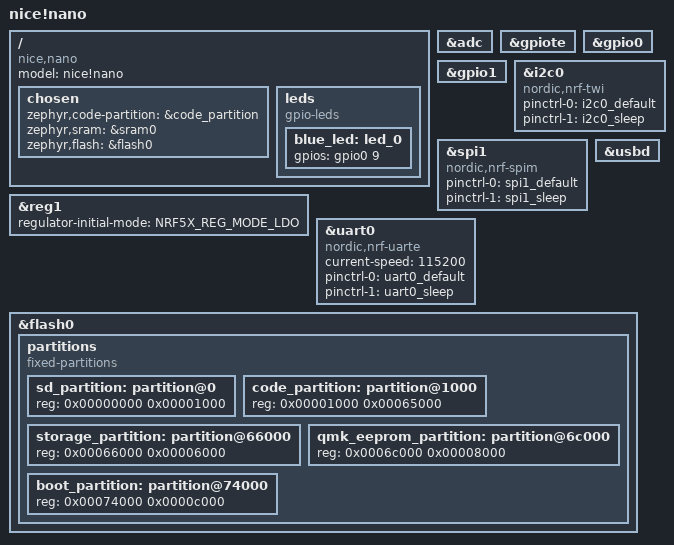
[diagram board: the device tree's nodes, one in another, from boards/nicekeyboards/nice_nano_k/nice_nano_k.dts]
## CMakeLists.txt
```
cmake_minimum_required(VERSION 3.13.1)

set(CONFIG_APPLICATION_DEFINED_SYSCALL true)
#D:/project/GitHub/zmkesb/zmk/zmk-feature-split-esb
set(ZEPHYR_BOARD_ALIASES "boards/aliases.cmake")
set(ZEPHYR_EXTRA_MODULES "${ZMK_EXTRA_MODULES};${CMAKE_CURRENT_SOURCE_DIR}/module;${CMAKE_CURRENT_SOURCE_DIR}/keymap-module")
message(STATUS "111111: ${CMAKE_CURRENT_SOURCE_DIR}")
list(APPEND ZEPHYR_EXTRA_MODULES
  "D:/project/GitHub/zmkesb/zmk-feature-split-esb-damex"
  # ${CMAKE_CURRENT_SOURCE_DIR}/../nrf
  # ${CMAKE_CURRENT_SOURCE_DIR}/../nrfxlib
)


# Find Zephyr. This also loads Zephyr's build system.
find_package(Zephyr REQUIRED HINTS ../zephyr)
project(zmk)

zephyr_linker_sources(SECTIONS include/linker/zmk-behaviors.ld)
zephyr_linker_sources(RODATA include/linker/zmk-events.ld)

if(CONFIG_ZMK_BEHAVIOR_LOCAL_IDS)
  zephyr_linker_sources(DATA_SECTIONS include/linker/zmk-behavior-local-id-map.ld)
endif()

zephyr_syscall_header(${APPLICATION_SOURCE_DIR}/include/drivers/behavior.h)
zephyr_syscall_header(${APPLICATION_SOURCE_DIR}/include/drivers/input_processor.h)
zephyr_syscall_header(${APPLICATION_SOURCE_DIR}/include/drivers/ext_power.h)

# Add your source file to the "app" target. This must come after
# find_package(Zephyr) which defines the target.
target_include_directories(app PRIVATE include)
add_subdirectory(src/boot)
target_sources(app PRIVATE src/stdlib.c)
target_sources(app PRIVATE src/activity.c)
target_sources(app PRIVATE src/behavior.c)
target_sources_ifdef(CONFIG_ZMK_KSCAN_SIDEBAND_BEHAVIORS app PRIVATE src/kscan_sideband_behaviors.c)
target_sources(app PRIVATE src/matrix_transform.c)
target_sources(app PRIVATE src/physical_layouts.c)
target_sources(app PRIVATE src/sensors.c)
target_sources_ifdef(CONFIG_ZMK_WPM app PRIVATE src/wpm.c)
target_sources(app PRIVATE src/event_manager.c)
target_sources_ifdef(CONFIG_ZMK_PM app PRIVATE src/pm.c)
target_sources_ifdef(CONFIG_ZMK_EXT_POWER app PRIVATE src/ext_power_generic.c)
target_sources_ifdef(CONFIG_ZMK_GPIO_KEY_WAKEUP_TRIGGER app PRIVATE src/gpio_key_wakeup_trigger.c)
target_sources(app PRIVATE src/events/activity_state_changed.c)
target_sources(app PRIVATE src/events/position_state_changed.c)
target_sources(app PRIVATE src/events/sensor_event.c)
target_sources_ifdef(CONFIG_ZMK_WPM app PRIVATE src/events/wpm_state_changed.c)
target_sources_ifdef(CONFIG_USB_DEVICE_STACK app PRIVATE src/events/usb_conn_state_changed.c)
target_sources(app PRIVATE src/behaviors/behavior_reset.c)
target_sources_ifdef(CONFIG_ZMK_EXT_POWER app PRIVATE src/behaviors/behavior_ext_power.c)
target_sources_ifdef(CONFIG_ZMK_BEHAVIOR_SOFT_OFF app PRIVATE src/behaviors/behavior_soft_off.c)
add_subdirectory_ifdef(CONFIG_ZMK_POINTING src/pointing/)
if ((NOT CONFIG_ZMK_SPLIT) OR CONFIG_ZMK_SPLIT_ROLE_CENTRAL)
  target_sources(app PRIVATE src/hid.c)
  target_sources(app PRIVATE src/behaviors/behavior_key_press.c)
  target_sources_ifdef(CONFIG_ZMK_BEHAVIOR_KEY_TOGGLE app PRIVATE src/behaviors/behavior_key_toggle.c)
  target_sources_ifdef(CONFIG_ZMK_BEHAVIOR_HOLD_TAP app PRIVATE src/behaviors/behavior_hold_tap.c)
  target_sources_ifdef(CONFIG_ZMK_BEHAVIOR_STICKY_KEY app PRIVATE src/behaviors/behavior_sticky_key.c)
  target_sources(app PRIVATE src/behaviors/behavior_caps_word.c)
  target_sources(app PRIVATE src/behaviors/behavior_key_repeat.c)
  target_sources_ifdef(CONFIG_ZMK_BEHAVIOR_MACRO app PRIVATE src/behaviors/behavior_macro.c)
  target_sources(app PRIVATE src/behaviors/behavior_momentary_layer.c)
  target_sources(app PRIVATE src/behaviors/behavior_mod_morph.c)
  target_sources(app PRIVATE src/behaviors/behavior_outputs.c)
  target_sources(app PRIVATE src/behaviors/behavior_toggle_layer.c)
  target_sources(app PRIVATE src/behaviors/behavior_to_layer.c)
  target_sources(app PRIVATE src/behaviors/behavior_transparent.c)
  target_sources(app PRIVATE src/behaviors/behavior_none.c)
  target_sources_ifdef(CONFIG_ZMK_BEHAVIOR_SENSOR_ROTATE app PRIVATE src/behaviors/behavior_sensor_rotate.c)
  target_sources_ifdef(CONFIG_ZMK_BEHAVIOR_SENSOR_ROTATE_VAR app PRIVATE src/behaviors/behavior_sensor_rotate_var.c)
  target_sources_ifdef(CONFIG_ZMK_BEHAVIOR_SENSOR_ROTATE_COMMON app PRIVATE src/behaviors/behavior_sensor_rotate_common.c)
  target_sources_ifdef(CONFIG_ZMK_BEHAVIOR_MOUSE_KEY_PRESS app PRIVATE src/behaviors/behavior_mouse_key_press.c)
  target_sources_ifdef(CONFIG_ZMK_BEHAVIOR_STUDIO_UNLOCK app PRIVATE src/behaviors/behavior_studio_unlock.c)
  target_sources_ifdef(CONFIG_ZMK_BEHAVIOR_INPUT_TWO_AXIS app PRIVATE src/behaviors/behavior_input_two_axis.c)
  target_sources(app PRIVATE src/combo.c)
  target_sources_ifdef(CONFIG_ZMK_BEHAVIOR_TAP_DANCE app PRIVATE src/behaviors/behavior_tap_dance.c)
  target_sources(app PRIVATE src/behavior_queue.c)
  target_sources(app PRIVATE src/conditional_layer.c)
  target_sources(app PRIVATE src/endpoints.c)
  target_sources(app PRIVATE src/events/endpoint_changed.c)
  target_sources(app PRIVATE src/hid_listener.c)
  target_sources(app PRIVATE src/keymap.c)
  target_sources(app PRIVATE src/events/layer_state_changed.c)
  target_sources(app PRIVATE src/events/modifiers_state_changed.c)
  target_sources(app PRIVATE src/events/keycode_state_changed.c)
  target_sources_ifdef(CONFIG_ZMK_HID_INDICATORS app PRIVATE src/hid_indicators.c)

  if (CONFIG_ZMK_BLE)
    target_sources(app PRIVATE src/events/ble_active_profile_changed.c)
    target_sources(app PRIVATE src/behaviors/behavior_bt.c)
    target_sources(app PRIVATE src/ble.c)
    target_sources(app PRIVATE src/hog.c)
  endif()
endif()

target_sources_ifdef(CONFIG_ZMK_RGB_UNDERGLOW app PRIVATE src/behaviors/behavior_rgb_underglow.c)
target_sources_ifdef(CONFIG_ZMK_BACKLIGHT app PRIVATE src/behaviors/behavior_backlight.c)

target_sources_ifdef(CONFIG_ZMK_BATTERY_REPORTING app PRIVATE src/events/battery_state_changed.c)
target_sources_ifdef(CONFIG_ZMK_BATTERY_REPORTING app PRIVATE src/battery.c)

target_sources_ifdef(CONFIG_ZMK_HID_INDICATORS app PRIVATE src/events/hid_indicators_changed.c)
add_subdirectory_ifdef(CONFIG_ZMK_HID_INDICATORS src/indicators)

target_sources_ifdef(CONFIG_ZMK_SPLIT app PRIVATE src/events/split_peripheral_status_changed.c)
add_subdirectory_ifdef(CONFIG_ZMK_SPLIT src/split)

target_sources_ifdef(CONFIG_USB_DEVICE_STACK app PRIVATE src/usb.c)
target_sources_ifdef(CONFIG_ZMK_USB app PRIVATE src/usb_hid.c)
target_sources_ifdef(CONFIG_ZMK_RGB_UNDERGLOW app PRIVATE src/rgb_underglow.c)
target_sources_ifdef(CONFIG_ZMK_BACKLIGHT app PRIVATE src/backlight.c)
target_sources_ifdef(CONFIG_ZMK_LOW_PRIORITY_WORK_QUEUE app PRIVATE src/workqueue.c)
target_sources(app PRIVATE src/main.c)

add_subdirectory(src/display/)
add_subdirectory_ifdef(CONFIG_SETTINGS src/settings/)

if (CONFIG_ZMK_STUDIO_RPC)
  # For some reason this is failing if run from a different sub-file.
  list(APPEND CMAKE_MODULE_PATH ${ZEPHYR_BASE}/modules/nanopb)

  include(nanopb)

    # Turn off the default nanopb behavior
  set(NANOPB_GENERATE_CPP_STANDALONE OFF)

  nanopb_generate_cpp(proto_srcs proto_hdrs RELPATH ${ZEPHYR_ZMK_STUDIO_MESSAGES_MODULE_DIR}
                        ${ZEPHYR_ZMK_STUDIO_MESSAGES_MODULE_DIR}/proto/zmk/studio.proto
                        ${ZEPHYR_ZMK_STUDIO_MESSAGES_MODULE_DIR}/proto/zmk/meta.proto
                        ${ZEPHYR_ZMK_STUDIO_MESSAGES_MODULE_DIR}/proto/zmk/core.proto
                        ${ZEPHYR_ZMK_STUDIO_MESSAGES_MODULE_DIR}/proto/zmk/behaviors.proto
                        ${ZEPHYR_ZMK_STUDIO_MESSAGES_MODULE_DIR}/proto/zmk/keymap.proto
  )

  target_include_directories(app PUBLIC ${CMAKE_CURRENT_BINARY_DIR})
  target_sources(app PRIVATE ${proto_srcs} ${proto_hdrs})

  add_subdirectory(src/studio)
endif()

zephyr_cc_option(-Wfatal-errors)
```

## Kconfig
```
# Copyright (c) 2020 The ZMK Contributors
# SPDX-License-Identifier: MIT

mainmenu "ZMK Firmware"

menu "ZMK"

config ZMK_BOARD_COMPAT
    bool
    help
      Hidden symbol used to hint that a board has been specifically
      set up with various ZMK requirements in mind, e.g. settings
      storage, bootloader integration, etc.

      Failure to set this will warn users they may want to verify they
      used a ZMK variant of an upstream board, or are using a board
      properly migrated to a newer ZMK version.

menu "Basic Keyboard Setup"

config ZMK_KEYBOARD_NAME
    string "Keyboard Name"

config USB_DEVICE_PRODUCT
    default ZMK_KEYBOARD_NAME

config BT_DEVICE_NAME
    default ZMK_KEYBOARD_NAME

config USB_DEVICE_VID
    default 0x1D50

config USB_DEVICE_PID
    default 0x615E

config USB_DEVICE_MANUFACTURER
    default "ZMK Project"

config BT_DIS_PNP_VID
    default 0x1D50

config BT_DIS_PNP_PID
    default 0x615E

config BT_DIS_MODEL_NUMBER_STR
    default ZMK_KEYBOARD_NAME

config BT_DIS_MANUF_NAME_STR
    default "ZMK Project"

# Hardware specific overrides

if SOC_SERIES_NRF52X

# Default on for our usage until boards implement retained bootmode.
config NRF_STORE_REBOOT_TYPE_GPREGRET
    bool
    default y

endif # SOC_SERIES_NRF52X

menu "HID"

choice ZMK_HID_REPORT_TYPE
    prompt "HID Report Type"

config ZMK_HID_REPORT_TYPE_HKRO
    bool "#-Key Roll Over (HKRO) HID Report"
    help
      Enable # key roll over for HID report. This selection is "boot keyboard" compatible
      but limits the total number of possible keys to report as held to #.

config ZMK_HID_REPORT_TYPE_NKRO
    bool "Full N-Key Roll Over (NKRO) HID Report"
    help
      Enable full N-Key Roll Over for HID output. This selection will prevent the keyboard
      from working with some BIOS/UEFI versions that only support "boot keyboard" support.
      This option also prevents using some infrequently used higher range HID usages (notably F13-F24 and INTL1-9)
      These usages can be re enabled with ZMK_HID_KEYBOARD_NKRO_EXTENDED_REPORT.

endchoice

config ZMK_HID_KEYBOARD_NKRO_EXTENDED_REPORT
    bool "Enable extended NKRO reporting"
    depends on ZMK_HID_REPORT_TYPE_NKRO
    help
      Enables higher usage range for NKRO (F13-F24 and INTL1-9).
      Please note this is not compatible with Android currently and you will get no input


if ZMK_HID_REPORT_TYPE_HKRO

config ZMK_HID_KEYBOARD_REPORT_SIZE
    int "# Keyboard Keys Reportable"

endif # ZMK_HID_REPORT_TYPE_HKRO

config ZMK_HID_CONSUMER_REPORT_SIZE
    int "# Consumer Keys Reportable"

choice ZMK_HID_CONSUMER_REPORT_USAGES
    prompt "HID Report Type"

config ZMK_HID_CONSUMER_REPORT_USAGES_FULL
    bool "Full Consumer HID Usage Support"
    help
      Enable full Consumer usage ID values to be sent to hosts. Allows for less
      frequently used usages, but has compatibability issues with some host OSes.

config ZMK_HID_CONSUMER_REPORT_USAGES_BASIC
    bool "Basic Consumer HID Usage Support"
    help
      Enable Consumer usage ID values up to "Playback Speed - Slow" to be sent to
      hosts. Allows for broader compatibability with more host OSes.

endchoice

config ZMK_HID_INDICATORS
    bool "HID Indicators"
    help
      Enable HID indicators, used for detecting state of Caps/Scroll/Num Lock,
      Kata, and Compose.

rsource "src/indicators/Kconfig"

config ZMK_HID_SEPARATE_MOD_RELEASE_REPORT
    bool "Release Modifiers Separately"
    help
      Send a separate release event for the modifiers, to make sure the release
      of the modifier doesn't get recognized before the actual key's release event.

menu "Output Types"

config ZMK_USB
    bool "USB"
    depends on (!ZMK_SPLIT || (ZMK_SPLIT && ZMK_SPLIT_ROLE_CENTRAL))
    select USB
    select USB_DEVICE_STACK
    select USB_DEVICE_HID

config ZMK_USB_BOOT
    bool "USB Boot Protocol Support"
    depends on ZMK_USB
    select USB_HID_BOOT_PROTOCOL

config USB_DEVICE_INITIALIZE_AT_BOOT
    default n

if ZMK_USB

config USB_NUMOF_EP_WRITE_RETRIES
    default 10

config USB_HID_POLL_INTERVAL_MS
    default 1

endif # ZMK_USB

menuconfig ZMK_BLE
    bool "BLE (HID over GATT)"
    select BT
    select BT_SMP
    select BT_SMP_SC_PAIR_ONLY
    select BT_SMP_APP_PAIRING_ACCEPT
    select BT_PERIPHERAL
    select BT_DIS
    imply BT_DEVICE_NAME_DYNAMIC
    imply BT_SETTINGS if !ARCH_POSIX
    imply SETTINGS if !ARCH_POSIX
    imply ZMK_BATTERY_REPORTING if !ARCH_POSIX

if ZMK_BLE

config ZMK_BLE_EXPERIMENTAL_CONN
    bool "Experimental BLE connection changes"
    help
      Enables settings that are planned to be default in future versions of ZMK
      to improve connection stability.

config ZMK_BLE_EXPERIMENTAL_SEC
    bool "Experimental BLE security changes"
    imply BT_SMP_ALLOW_UNAUTH_OVERWRITE
    help
      Enables security settings that are planned to be officially supported in the future.

config ZMK_BLE_EXPERIMENTAL_FEATURES
    bool "Experimental BLE connection and security settings/features"
    select ZMK_BLE_EXPERIMENTAL_CONN
    select ZMK_BLE_EXPERIMENTAL_SEC
    help
      Enables experimental connection changes and security features.

config ZMK_BLE_PASSKEY_ENTRY
    bool "Require passkey entry on the keyboard to complete pairing"
    select RING_BUFFER

config BT_SMP_ALLOW_UNAUTH_OVERWRITE
    imply ZMK_BLE_PASSKEY_ENTRY

config BT_CTLR_PHY_2M
    default n if ZMK_BLE_EXPERIMENTAL_CONN

config ZMK_BLE_THREAD_STACK_SIZE
    int "BLE notify thread stack size"
    default 768

config ZMK_BLE_THREAD_PRIORITY
    int "BLE notify thread priority"
    default 5

config ZMK_BLE_KEYBOARD_REPORT_QUEUE_SIZE
    int "Max number of keyboard HID reports to queue for sending over BLE"
    default 20

config ZMK_BLE_CONSUMER_REPORT_QUEUE_SIZE
    int "Max number of consumer HID reports to queue for sending over BLE"
    default 5

config ZMK_BLE_MOUSE_REPORT_QUEUE_SIZE
    int "Max number of mouse HID reports to queue for sending over BLE"
    default 20

config ZMK_BLE_CLEAR_BONDS_ON_START
    bool "Configuration that clears all bond information from the keyboard on startup."

# HID GATT notifications sent this way are *not* picked up by Linux, and possibly others.
config BT_GATT_NOTIFY_MULTIPLE
    default n

config BT_GATT_AUTO_SEC_REQ
    default (ZMK_SPLIT_BLE && !ZMK_SPLIT_ROLE_CENTRAL)

config BT_PERIPHERAL_PREF_MIN_INT
    default 6

config BT_PERIPHERAL_PREF_MAX_INT
    default 12

config BT_PERIPHERAL_PREF_LATENCY
    default 30

config BT_PERIPHERAL_PREF_TIMEOUT
    default 400

# The device name should be 16 characters or less so it fits within the
# advertising data.
config BT_DEVICE_NAME_MAX
    default 16

endif # ZMK_BLE

endmenu # Output Types

endmenu # HID

rsource "src/split/Kconfig"

endmenu # Basic Keyboard Setup

menu "Keymaps"

config ZMK_KEYMAP_LAYER_REORDERING
    bool "Layer Reordering Support"

config ZMK_KEYMAP_SETTINGS_STORAGE
    bool "Settings Save/Load"
    depends on SETTINGS
    depends on ZMK_BEHAVIOR_LOCAL_IDS

if ZMK_KEYMAP_SETTINGS_STORAGE

config ZMK_KEYMAP_LAYER_NAME_MAX_LEN
    int "Max Layer Name Length"
    default 20

endif # ZMK_KEYMAP_SETTINGS_STORAGE

endmenu # Keymaps

rsource "src/studio/Kconfig"

menu "Display/LED Options"

rsource "src/display/Kconfig"

menuconfig ZMK_RGB_UNDERGLOW
    bool "RGB Addressable LED Underglow"
    select LED_STRIP
    select ZMK_LOW_PRIORITY_WORK_QUEUE

if ZMK_RGB_UNDERGLOW

config ZMK_RGB_UNDERGLOW_EXT_POWER
    bool "RGB underglow toggling also controls external power"

config ZMK_RGB_UNDERGLOW_BRT_MIN
    int "RGB underglow minimum brightness in percent"
    range 0 100

config ZMK_RGB_UNDERGLOW_BRT_MAX
    int "RGB underglow maximum brightness in percent"
    range ZMK_RGB_UNDERGLOW_BRT_MIN 100

config ZMK_RGB_UNDERGLOW_HUE_STEP
    int "RGB underglow hue step in degrees"
    range 0 359

config ZMK_RGB_UNDERGLOW_SAT_STEP
    int "RGB underglow saturation step in percent"
    range 0 100

config ZMK_RGB_UNDERGLOW_BRT_STEP
    int "RGB underglow brightness step in percent"
    range 0 100

config ZMK_RGB_UNDERGLOW_HUE_START
    int "RGB underglow start hue value in degrees"
    range 0 359

config ZMK_RGB_UNDERGLOW_SAT_START
    int "RGB underglow start saturations value in percent"
    range 0 100

config ZMK_RGB_UNDERGLOW_BRT_START
    int "RGB underglow start brightness value in percent"
    range ZMK_RGB_UNDERGLOW_BRT_MIN ZMK_RGB_UNDERGLOW_BRT_MAX

config ZMK_RGB_UNDERGLOW_SPD_START
    int "RGB underglow start animation speed value"
    range 1 5

config ZMK_RGB_UNDERGLOW_EFF_START
    int "RGB underglow start effect int value related to the effect enum list"
    range 0 3

config ZMK_RGB_UNDERGLOW_ON_START
    bool "RGB underglow starts on by default"

config ZMK_RGB_UNDERGLOW_AUTO_OFF_IDLE
    bool "Turn off RGB underglow when keyboard goes into idle state"

config ZMK_RGB_UNDERGLOW_AUTO_OFF_USB
    bool "Turn off RGB underglow when USB is disconnected"
    depends on USB_DEVICE_STACK

endif # ZMK_RGB_UNDERGLOW

menuconfig ZMK_BACKLIGHT
    bool "LED backlight"
    select LED

if ZMK_BACKLIGHT

config ZMK_BACKLIGHT_BRT_STEP
    int "Brightness step in percent"
    range 1 100

config ZMK_BACKLIGHT_BRT_START
    int "Default brightness in percent"
    range 1 100

config ZMK_BACKLIGHT_ON_START
    bool "Default backlight state"

config ZMK_BACKLIGHT_AUTO_OFF_IDLE
    bool "Turn off backlight when keyboard goes into idle state"

config ZMK_BACKLIGHT_AUTO_OFF_USB
    bool "Turn off backlight when USB is disconnected"

endif # ZMK_BACKLIGHT

endmenu # Display/LED Options

rsource "src/pointing/Kconfig"

menu "Power Management"

config ZMK_BATTERY_REPORTING
    bool "Battery level detection/reporting"
    select SENSOR
    select ZMK_LOW_PRIORITY_WORK_QUEUE
    imply BT_BAS if ZMK_BLE

if ZMK_BATTERY_REPORTING

choice ZMK_BATTERY_REPORTING_FETCH_MODE
    prompt "Battery Reporting Fetch Mode"

config ZMK_BATTERY_REPORTING_FETCH_MODE_STATE_OF_CHARGE
    bool "State of charge"

config ZMK_BATTERY_REPORTING_FETCH_MODE_LITHIUM_VOLTAGE
    bool "Lithium Voltage"

endchoice

endif # ZMK_BATTERY_REPORTING

config ZMK_IDLE_TIMEOUT
    int "Milliseconds of inactivity before entering idle state (OLED shutoff, etc)"
    default 30000

config ZMK_SLEEP
    bool "Enable deep sleep support"
    depends on HAS_POWEROFF
    select POWEROFF
    select ZMK_PM_DEVICE_SUSPEND_RESUME
    imply USB

if ZMK_SLEEP

config PM_DEVICE
    default y

config ZMK_IDLE_SLEEP_TIMEOUT
    int "Milliseconds of inactivity before entering deep sleep"
    default 900000

endif # ZMK_SLEEP

config ZMK_EXT_POWER
    bool "Enable support to control external power output"

config ZMK_PM
    bool

config ZMK_PM_DEVICE_SUSPEND_RESUME
    bool
    select ZMK_PM

config ZMK_PM_SOFT_OFF
    bool "Soft-off support"
    depends on HAS_POWEROFF
    select ZMK_PM
    select PM_DEVICE
    select ZMK_PM_DEVICE_SUSPEND_RESUME
    select POWEROFF

config ZMK_GPIO_KEY_WAKEUP_TRIGGER
    bool "Hardware supported wakeup (GPIO)"
    default y
    depends on DT_HAS_ZMK_GPIO_KEY_WAKEUP_TRIGGER_ENABLED && ZMK_PM_SOFT_OFF

# Power Management
endmenu

menu "Combo options"

config ZMK_COMBO_MAX_PRESSED_COMBOS
    int "Maximum number of currently pressed combos"
    default 4

config ZMK_COMBO_MAX_COMBOS_PER_KEY
    int "Deprecated: Max combos per key"
    default 0
    help
      Deprecated: Storage for combos is now determined automatically

config ZMK_COMBO_MAX_KEYS_PER_COMBO
    int "Deprecated: Max keys per combo"
    default 0
    help
       Deprecated: This is now auto-calculated based on `key-positions` in devicetree

# Combo options
endmenu

menu "Behavior Options"

config ZMK_BEHAVIORS_QUEUE_SIZE
    int "Maximum number of behaviors to allow queueing from a macro or other complex behavior"
    default 64

rsource "Kconfig.behaviors"

config ZMK_MACRO_DEFAULT_WAIT_MS
    int "Default time to wait (in milliseconds) before triggering the next behavior in macros"
    default 15

config ZMK_MACRO_DEFAULT_TAP_MS
    int "Default time to wait (in milliseconds) between the press and release events of a tapped behavior in macros"
    default 30

endmenu

menu "Advanced"

rsource "src/boot/Kconfig"

menu "Initialization Priorities"

if USB_DEVICE_STACK

config ZMK_USB_INIT_PRIORITY
    int "USB Init Priority"
    default 96

config ZMK_USB_HID_INIT_PRIORITY
    int "USB HID Init Priority"
    default 95

endif # USB

if ZMK_BLE || ZMK_SPLIT_BLE

config ZMK_BLE_INIT_PRIORITY
    int "BLE Init Priority"
    default 50

endif # ZMK_BLE || ZMK_SPLIT_BLE

endmenu # Initialization Priorities

config ZMK_PHYSICAL_LAYOUT_KEY_ROTATION
    bool "Support rotation of keys in physical layouts"
    default y

menuconfig ZMK_KSCAN
    bool "ZMK KScan Integration"
    default y
    select KSCAN

if ZMK_KSCAN

config ZMK_KSCAN_EVENT_QUEUE_SIZE
    int "Size of the event queue for KSCAN events to buffer events"
    default 4

endif # ZMK_KSCAN

config ZMK_KSCAN_SIDEBAND_BEHAVIORS
    bool
    default y
    depends on DT_HAS_ZMK_KSCAN_SIDEBAND_BEHAVIORS_ENABLED
    select KSCAN

if ZMK_KSCAN_SIDEBAND_BEHAVIORS

config ZMK_KSCAN_SIDEBAND_BEHAVIORS_INIT_PRIORITY
    int "Keyboard scan sideband behaviors driver init priority"
    # The default kscan init priority is 90, so be sure we are initialized later.
    default 95

endif # ZMK_KSCAN_SIDEBAND_BEHAVIORS

menu "Logging"

config ZMK_LOGGING_MINIMAL
    bool "Suppress all ZMK debug log messages"
    default false

if !ZMK_LOGGING_MINIMAL

config ZMK_LOG_LEVEL
    default 4

endif

config ZMK_USB_LOGGING
    bool "Enable USB CDC ACM logging to help debug"
    select LOG
    select USB
    select USB_DEVICE_STACK
    select USB_CDC_ACM
    select SERIAL
    select CONSOLE
    select UART_INTERRUPT_DRIVEN
    select UART_LINE_CTRL
    select UART_CONSOLE
    select USB_UART_CONSOLE

if ZMK_USB_LOGGING

choice USB_CDC_ACM_LOG_LEVEL_CHOICE
    default USB_CDC_ACM_LOG_LEVEL_OFF
endchoice

choice USB_DRIVER_LOG_LEVEL_CHOICE
    default USB_DRIVER_LOG_LEVEL_OFF
endchoice

# We do this to avoid log loop where logging to USB generates more log messages.

config USB_CDC_ACM_RINGBUF_SIZE
    default 1024

config LOG_PROCESS_THREAD_STARTUP_DELAY_MS
    default 1000

endif # ZMK_USB_LOGGING

config ZMK_RTT_LOGGING
    bool "Enable RTT logging to help debug"
    select LOG
    select DEBUG
    select ASSERT
    select USE_SEGGER_RTT
    select CONSOLE
    select RTT_CONSOLE

if ZMK_RTT_LOGGING

config SEGGER_RTT_BUFFER_SIZE_UP
    default 8192

endif # ZMK_RTT_LOGGING

if ZMK_USB_LOGGING || ZMK_RTT_LOGGING

config LOG_BUFFER_SIZE
    default 8192

config LOG_PROCESS_THREAD_SLEEP_MS
    default 100

endif # ZMK_USB_LOGGING || ZMK_RTT_LOGGING

endmenu # Logging

if SETTINGS

config ZMK_SETTINGS_RESET_ON_START
    bool "Delete all persistent settings when the keyboard boots"

if ZMK_SETTINGS_RESET_ON_START

config ZMK_SETTINGS_RESET_ON_START_INIT_PRIORITY
    int "Settings Reset ON Start Initialization Priority"
    default 60
    help
      Initialization priority for the settings reset on start. Must be lower priority/
      higher value than FLASH_INIT_PRIORITY if using the NVS/Flash settings backend.

endif # ZMK_SETTINGS_RESET_ON_START

config ZMK_SETTINGS_SAVE_DEBOUNCE
    int "Milliseconds to debounce settings saves"
    default 60000

endif # SETTINGS

config ZMK_BATTERY_REPORT_INTERVAL
    depends on ZMK_BATTERY_REPORTING
    int "Battery level report interval in seconds"

config ZMK_LOW_PRIORITY_WORK_QUEUE
    bool "Work queue for low priority items"

if ZMK_LOW_PRIORITY_WORK_QUEUE

config ZMK_LOW_PRIORITY_THREAD_STACK_SIZE
    int "Low priority thread stack size"
    default 768

config ZMK_LOW_PRIORITY_THREAD_PRIORITY
    int "Low priority thread priority"
    default 10

endif # ZMK_LOW_PRIORITY_WORK_QUEUE

endmenu # Advanced

endmenu # ZMK

if SOC_FAMILY_NORDIC_NRF

config NRF_SOC_VALIDATE_HEADERS_DISABLED
    default y

endif

config KERNEL_BIN_NAME
    default "zmk"

config REBOOT
    default y

config USB_DEVICE_STACK
    default y if HAS_HW_NRF_USBD

config FPU
    default CPU_HAS_FPU

config ZMK_WPM
    bool "Calculate WPM"

config ZMK_KEYMAP_SENSORS
    bool "Enable Keymap Sensors support"
    default y
    depends on DT_HAS_ZMK_KEYMAP_SENSORS_ENABLED
    select SENSOR

if ZMK_KEYMAP_SENSORS

config ZMK_KEYMAP_SENSORS_DEFAULT_TRIGGERS_PER_ROTATION
    int "Default triggers per rotation"
    help
      Unless overridden for a sensor in the board/shield/devicetree, this value
      determines how many times to trigger the bound behavior per full rotation.
      For tactile encoders with detents, this usually should match the number of
      detents per rotation of the encoder.
    default 20

endif # ZMK_KEYMAP_SENSORS

module = ZMK
module-str = zmk
source "subsys/logging/Kconfig.template.log_config"

# This loads ZMK's internal board and shield Kconfigs
rsource "boards/Kconfig"
rsource "boards/shields/*/Kconfig.defconfig"
rsource "boards/shields/*/Kconfig.shield"

# This loads custom shields defconfigs (from BOARD_ROOT)
# Duplicated from Kconfig.zephyr
osource "$(KCONFIG_BINARY_DIR)/Kconfig.shield.defconfig"

# This loads board and shield Kconfigs found under zmk-config/config/
# osource "$(ZMK_CONFIG)/boards/shields/*/Kconfig.defconfig"
# osource "$(ZMK_CONFIG)/boards/shields/*/Kconfig.shield"

# This loads ZMK's sensible defaults
rsource "Kconfig.defaults"

source "Kconfig.zephyr"
```

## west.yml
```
manifest:
  remotes:
    - name: zephyrproject-rtos
      url-base: https://github.com/zephyrproject-rtos
    - name: zmkfirmware
      url-base: https://github.com/zmkfirmware
    - name: kbladewht # <--- add this
      url-base: https://github.com/kbladewht # <--- and this
  projects:
    - name: zephyr
      remote: zmkfirmware
      revision: v4.1.0+zmk-fixes
      clone-depth: 1
      import:
        name-blocklist:
          - ci-tools
          - hal_altera
          - hal_cypress
          - hal_infineon
          - hal_microchip
          - hal_nxp
          - hal_openisa
          - hal_xtensa
          - hal_st
          - hal_ti
          - loramac-node
          - mcuboot
          - mcumgr
          - net-tools
          - openthread
          - edtt
          - trusted-firmware-m
    - name: hal_stm32
      revision: 4fcc3a3f32abe1c4cb76d9d1cef967728dd03908
      path: modules/hal/stm32
      remote: zmkfirmware
      groups:
        - hal
    - name: lvgl
      revision: f1db87ee98f1810328a8419572fa42a3b5f352ae
      path: modules/lib/gui/lvgl
      remote: zmkfirmware
    - name: zmk-studio-messages
      revision: 6cb4c283e76209d59c45fbcb218800cd19e9339d
      path: modules/msgs/zmk-studio-messages
      remote: zmkfirmware
    - name: prospector-zmk-module
      remote: kbladewht
      revision: master
      path: prospector-zmk-module
  group-filter: [+optional]
  self:
    west-commands: scripts/west-commands.yml
```

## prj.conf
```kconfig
CONFIG_APPLICATION_DEFINED_SYSCALL=y

CONFIG_NRF_SECURITY=n
```

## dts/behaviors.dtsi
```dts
/*
 * Copyright (c) 2024 The ZMK Contributors
 *
 * SPDX-License-Identifier: MIT
 */

#include <behaviors/key_press.dtsi>
#include <behaviors/key_toggle.dtsi>
#include <behaviors/transparent.dtsi>
#include <behaviors/none.dtsi>
#include <behaviors/mod_tap.dtsi>
#include <behaviors/layer_tap.dtsi>
#include <behaviors/gresc.dtsi>
#include <behaviors/sticky_key.dtsi>
#include <behaviors/momentary_layer.dtsi>
#include <behaviors/toggle_layer.dtsi>
#include <behaviors/to_layer.dtsi>
#include <behaviors/to_esb.dtsi>
#include <behaviors/reset.dtsi>
#include <behaviors/sensor_rotate_key_press.dtsi>
#include <behaviors/rgb_underglow.dtsi>
#include <behaviors/bluetooth.dtsi>
#include <behaviors/ext_power.dtsi>
#include <behaviors/outputs.dtsi>
#include <behaviors/caps_word.dtsi>
#include <behaviors/key_repeat.dtsi>
#include <behaviors/backlight.dtsi>
#include <behaviors/macros.dtsi>
#include <behaviors/soft_off.dtsi>
#include <behaviors/studio_unlock.dtsi>
#include <behaviors/mouse_keys.dtsi>
```

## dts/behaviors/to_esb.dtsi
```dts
/*
 * Copyright (c) 2020 The ZMK Contributors
 *
 * SPDX-License-Identifier: MIT
 */

#include <dt-bindings/zmk/behaviors.h>

/ {
    behaviors {
        to_esb: to_esb {
            compatible = "zmk,behavior-to-esb";
            #binding-cells = <1>;
            status = "okay";   // ← 这一行非常关键
            display-name = "To ESB";
            esb_mode;
        };
    };
};
```

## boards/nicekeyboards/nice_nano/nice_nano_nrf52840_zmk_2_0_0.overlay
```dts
/*
 * Copyright (c) 2021 The ZMK Contributors
 *
 * SPDX-License-Identifier: MIT
 */

/ {
    chosen {
        zmk,battery = &vbatt;
    };

    // Node name must match original "EXT_POWER" label to preserve user settings.
    EXT_POWER {
        compatible = "zmk,ext-power-generic";
        control-gpios = <&gpio0 13 GPIO_ACTIVE_HIGH>;
        init-delay-ms = <50>;
    };

    vbatt: vbatt {
        compatible = "zmk,battery-nrf-vddh";
    };
};
ddd
&reg0 {
    status = "okay";
};
```

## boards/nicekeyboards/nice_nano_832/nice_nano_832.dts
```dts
/*
 * Copyright (c) 2021 The ZMK Contributors
 *
 * SPDX-License-Identifier: MIT
 */

/dts-v1/;

#include <nordic/nrf52832_qfaa.dtsi>
// #include <common/nordic/nrf52833_uf2_boot_mode.dtsi>

#include "nice_nano_832-pinctrl.dtsi"
// #include "arduino_pro_micro_pins.dtsi"


/ {
    model = "nice!nano";
    compatible = "nice,nano";

    chosen {
        zephyr,code-partition = &code_partition;
        zephyr,sram = &sram0;
        zephyr,flash = &flash0;
    };

    leds {
        compatible = "gpio-leds";
        blue_led: led_0 {
            gpios = <&gpio0 9 GPIO_ACTIVE_HIGH>;
        };
    };
};

&uicr {
    nfct-pins-as-gpios;
    gpio-as-nreset;
};

&adc {
    status = "okay";
};

&gpiote {
    status = "okay";
};

&gpio0 {
    status = "okay";
};



&i2c0 {
    compatible = "nordic,nrf-twi";
    pinctrl-0 = <&i2c0_default>;
    pinctrl-1 = <&i2c0_sleep>;
    pinctrl-names = "default", "sleep";
};

&spi1 {
    compatible = "nordic,nrf-spim";
    pinctrl-0 = <&spi1_default>;
    pinctrl-1 = <&spi1_sleep>;
    pinctrl-names = "default", "sleep";
};

&uart0 {
    compatible = "nordic,nrf-uarte";
    current-speed = <115200>;
    pinctrl-0 = <&uart0_default>;
    pinctrl-1 = <&uart0_sleep>;
    pinctrl-names = "default", "sleep";
};



&flash0 {
    /*
     * For more information, see:
     * http://docs.zephyrproject.org/latest/devices/dts/flash_partitions.html
     */
    partitions {
        compatible = "fixed-partitions";
        #address-cells = <1>;
        #size-cells = <1>;

        sd_partition: partition@0 {
            reg = <0x00000000 0x00001000>;//System reserved
        };

        code_partition: partition@1000 {
            reg = <0x00001000 0x00065000>; //248K (152k-400k)
        };

        // code_partition: partition@18000 {
        //     reg = <0x00018000 0x0004e000>; //396K (96K-400k)
        // };

        storage_partition: partition@66000 {
            reg = <0x00066000 0x00006000>;//24K (408K-432K)
        };

        qmk_eeprom_partition: partition@6c000 {
            reg = <0x0006c000 0x00006000>;//(432K-456k)
        };

        qmk_eeprom_esb_partition: partition@72000 {
            reg = <0x00072000 0x00002000>;//(456K-464k)
        };

        boot_partition: partition@74000 {//464k-512k 48k
            reg = <0x00074000 0x0000c000>;
        };
    };
};
```

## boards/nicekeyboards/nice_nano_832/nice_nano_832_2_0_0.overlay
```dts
/*
 * Copyright (c) 2021 The ZMK Contributors
 *
 * SPDX-License-Identifier: MIT
 */

/ {
    chosen {
        zmk,battery = &vbatt;
    };

    // // Node name must match original "EXT_POWER" label to preserve user settings.
    // EXT_POWER {
    //     compatible = "zmk,ext-power-generic";
    //     control-gpios = <&gpio0 3 GPIO_ACTIVE_HIGH>;
    //     init-delay-ms = <50>;
    // };

    // vbatt: vbatt {
    //     compatible = "zmk,battery-nrf-vddh";
    // };

     vbatt: vbatt {
        compatible = "zmk,battery-voltage-divider";
        io-channels = <&adc 2>;
        output-ohms = <2000000>;
        full-ohms = <(2000000 + 806000)>;
    };
};
```

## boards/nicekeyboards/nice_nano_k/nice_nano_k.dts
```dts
/*
 * Copyright (c) 2021 The ZMK Contributors
 *
 * SPDX-License-Identifier: MIT
 */

/dts-v1/;

#include <nordic/nrf52833_qdaa.dtsi>
#include <common/nordic/nrf52833_uf2_boot_mode.dtsi>

#include "nice_nano_k-pinctrl.dtsi"
// #include "arduino_pro_micro_pins.dtsi"


/ {
    model = "nice!nano";
    compatible = "nice,nano";

    chosen {
        zephyr,code-partition = &code_partition;
        zephyr,sram = &sram0;
        zephyr,flash = &flash0;
    };

    leds {
        compatible = "gpio-leds";
        blue_led: led_0 {
            gpios = <&gpio0 9 GPIO_ACTIVE_HIGH>;
        };
    };
};

&reg1 {
    regulator-initial-mode = <NRF5X_REG_MODE_LDO>;
};

&adc {
    status = "okay";
};

&gpiote {
    status = "okay";
};

&gpio0 {
    status = "okay";
};

&gpio1 {
    status = "okay";
};

&i2c0 {
    compatible = "nordic,nrf-twi";
    pinctrl-0 = <&i2c0_default>;
    pinctrl-1 = <&i2c0_sleep>;
    pinctrl-names = "default", "sleep";
};

&spi1 {
    compatible = "nordic,nrf-spim";
    pinctrl-0 = <&spi1_default>;
    pinctrl-1 = <&spi1_sleep>;
    pinctrl-names = "default", "sleep";
};

&uart0 {
    compatible = "nordic,nrf-uarte";
    current-speed = <115200>;
    pinctrl-0 = <&uart0_default>;
    pinctrl-1 = <&uart0_sleep>;
    pinctrl-names = "default", "sleep";
};

zephyr_udc0: &usbd {
    status = "okay";
};


&flash0 {
    /*
     * For more information, see:
     * http://docs.zephyrproject.org/latest/devices/dts/flash_partitions.html
     */
    partitions {
        compatible = "fixed-partitions";
        #address-cells = <1>;
        #size-cells = <1>;

        sd_partition: partition@0 {
            reg = <0x00000000 0x00001000>;//System reserved
        };
        // qmkcode_partition: partition@1000 {
        //     reg = <0x00001000 0x00017000>;//92K （4k-96KB）
        // };
        code_partition: partition@1000 {
            reg = <0x00001000 0x00065000>; //396K (4k-400k)
        };

        // code_partition: partition@18000 {
        //     reg = <0x00018000 0x0004e000>; //396K (96K-400k)
        // };

        storage_partition: partition@66000 {
            reg = <0x00066000 0x00006000>;//24K (408K-432K)
        };

        qmk_eeprom_partition: partition@6c000 {
            reg = <0x0006c000 0x00008000>;//(432K-456k)
        };

        boot_partition: partition@74000 {//464k-512k 48k
            reg = <0x00074000 0x0000c000>;
        };
    };
};
```

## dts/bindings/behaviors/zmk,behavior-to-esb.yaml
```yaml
# Copyright (c) 2020 The ZMK Contributors
# SPDX-License-Identifier: MIT

description: To ESB

compatible: "zmk,behavior-to-esb"

include: one_param.yaml

properties:
  esb_mode:
    type: boolean
    description: switch to esb mode
```

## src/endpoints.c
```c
/*
 * Copyright (c) 2020 The ZMK Contributors
 *
 * SPDX-License-Identifier: MIT
 */

#include <zephyr/init.h>
#include <zephyr/settings/settings.h>

#include <stdio.h>

#include <zmk/ble.h>
#include <zmk/endpoints.h>
#include <zmk/hid.h>
#include <dt-bindings/zmk/hid_usage_pages.h>
#include <zmk/usb_hid.h>
#include <zmk/hog.h>
#include <zmk/endpoints.h>
#include <zmk/event_manager.h>
#include <zmk/events/ble_active_profile_changed.h>
#include <zmk/events/usb_conn_state_changed.h>
#include <zmk/events/endpoint_changed.h>

#include <zephyr/logging/log.h>

LOG_MODULE_DECLARE(zmk, CONFIG_ZMK_LOG_LEVEL);

// Name of the subtree for endpoint-related settings
#define SETTING_SUBTREE "endpoints"

// Key of the setting to store the preferred_transport value.
#define SETTING_PREFERRED_TRANSPORT_KEY "preferred2"
// Full name of the setting to store the preferred_transport value.
#define SETTING_PREFERRED_TRANSPORT SETTING_SUBTREE "/" SETTING_PREFERRED_TRANSPORT_KEY

// Key of the deprecated setting which stored preferred_transport with an older type.
#define SETTING_PREFERRED_TRANSPORT_V1_KEY "preferred"
// Full name of the deprecated setting which stored preferred_transport with an older type.
#define SETTING_PREFERRED_TRANSPORT_V1 SETTING_SUBTREE "/" SETTING_PREFERRED_TRANSPORT_V1_KEY

#if IS_ENABLED(CONFIG_ZMK_USB)
#define DEFAULT_TRANSPORT ZMK_TRANSPORT_USB
#elif IS_ENABLED(CONFIG_ZMK_BLE)
#define DEFAULT_TRANSPORT ZMK_TRANSPORT_BLE
#else
#define DEFAULT_TRANSPORT ZMK_TRANSPORT_NONE
#endif

static struct zmk_endpoint_instance current_instance = {};

// Transport to use if multiple endpoints are ready
static enum zmk_transport preferred_transport = DEFAULT_TRANSPORT;

static void update_current_endpoint(void);

#if IS_ENABLED(CONFIG_SETTINGS)
static void endpoints_save_preferred_work(struct k_work *work) { settings_save_one(SETTING_PREFERRED_TRANSPORT, &preferred_transport, sizeof(preferred_transport)); }

static struct k_work_delayable endpoints_save_work;
#endif

static int endpoints_save_preferred(void) {
#if IS_ENABLED(CONFIG_SETTINGS)
    return k_work_reschedule(&endpoints_save_work, K_MSEC(CONFIG_ZMK_SETTINGS_SAVE_DEBOUNCE));
#else
    return 0;
#endif
}

bool zmk_endpoint_instance_eq(struct zmk_endpoint_instance a, struct zmk_endpoint_instance b) {
    if (a.transport != b.transport) {
        return false;
    }

    switch (a.transport) {
    case ZMK_TRANSPORT_NONE:
    case ZMK_TRANSPORT_USB:
        return true;

    case ZMK_TRANSPORT_BLE:
        return a.ble.profile_index == b.ble.profile_index;
    }

    LOG_ERR("Invalid transport %d", a.transport);
    return false;
}

int zmk_endpoint_instance_to_str(struct zmk_endpoint_instance endpoint, char *str, size_t len) {
    switch (endpoint.transport) {
    case ZMK_TRANSPORT_NONE:
        return snprintf(str, len, "None");

    case ZMK_TRANSPORT_USB:
        return snprintf(str, len, "USB");

    case ZMK_TRANSPORT_BLE:
        return snprintf(str, len, "BLE:%d", endpoint.ble.profile_index);

    default:
        return snprintf(str, len, "Invalid");
    }
}

#define INSTANCE_INDEX_OFFSET_NONE 0
#define INSTANCE_INDEX_OFFSET_USB (INSTANCE_INDEX_OFFSET_NONE + ZMK_ENDPOINT_NONE_COUNT)
#define INSTANCE_INDEX_OFFSET_BLE (INSTANCE_INDEX_OFFSET_USB + ZMK_ENDPOINT_USB_COUNT)

int zmk_endpoint_instance_to_index(struct zmk_endpoint_instance endpoint) {
    switch (endpoint.transport) {
    case ZMK_TRANSPORT_NONE:
        return INSTANCE_INDEX_OFFSET_NONE;

    case ZMK_TRANSPORT_USB:
        return INSTANCE_INDEX_OFFSET_USB;

    case ZMK_TRANSPORT_BLE:
        return INSTANCE_INDEX_OFFSET_BLE + endpoint.ble.profile_index;
    }

    LOG_ERR("Invalid transport %d", endpoint.transport);
    return 0;
}

int zmk_endpoint_set_preferred_transport(enum zmk_transport transport) {
    LOG_DBG("Selected endpoint transport %d", transport);

    if (preferred_transport == transport) {
        return 0;
    }

    preferred_transport = transport;

    endpoints_save_preferred();

    update_current_endpoint();

    return 0;
}

enum zmk_transport zmk_endpoint_get_preferred_transport(void) { return preferred_transport; }

int zmk_endpoint_toggle_preferred_transport(void) {
    enum zmk_transport new_transport = (preferred_transport == ZMK_TRANSPORT_USB) ? ZMK_TRANSPORT_BLE : ZMK_TRANSPORT_USB;
    return zmk_endpoint_set_preferred_transport(new_transport);
}

static struct zmk_endpoint_instance get_instance_from_transport(enum zmk_transport transport) {
    struct zmk_endpoint_instance instance = {.transport = transport};
    switch (instance.transport) {
    case ZMK_TRANSPORT_BLE:
#if IS_ENABLED(CONFIG_ZMK_BLE)
        instance.ble.profile_index = zmk_ble_active_profile_index();
#endif // IS_ENABLED(CONFIG_ZMK_BLE)
        break;

    default:
        // No extra data for this transport.
        break;
    }

    return instance;
}

struct zmk_endpoint_instance zmk_endpoint_get_preferred(void) { return get_instance_from_transport(preferred_transport); }

struct zmk_endpoint_instance zmk_endpoint_get_selected(void) { return current_instance; }

bool zmk_endpoint_is_connected(void) { return current_instance.transport != ZMK_TRANSPORT_NONE; }

static int send_keyboard_report(void) {
    switch (current_instance.transport) {
    case ZMK_TRANSPORT_NONE:
        return 0;

    case ZMK_TRANSPORT_USB: {
#if IS_ENABLED(CONFIG_ZMK_USB)
        int err = zmk_usb_hid_send_keyboard_report();
        if (err) {
            LOG_ERR("FAILED TO SEND OVER USB: %d", err);
        }
        return err;
#else
        LOG_ERR("USB endpoint is not supported");
        return -ENOTSUP;
#endif /* IS_ENABLED(CONFIG_ZMK_USB) */
    }

    case ZMK_TRANSPORT_BLE: {
#if IS_ENABLED(CONFIG_ZMK_BLE)
        struct zmk_hid_keyboard_report *keyboard_report = zmk_hid_get_keyboard_report();
        int err = zmk_hog_send_keyboard_report(&keyboard_report->body);
        if (err) {
            LOG_ERR("FAILED TO SEND OVER HOG: %d", err);
        }
        return err;
#else
        LOG_ERR("BLE HOG endpoint is not supported");
        return -ENOTSUP;
#endif /* IS_ENABLED(CONFIG_ZMK_BLE) */
    }
    }

    LOG_ERR("Unhandled endpoint transport %d", current_instance.transport);
    return -ENOTSUP;
}

static int send_consumer_report(void) {
    switch (current_instance.transport) {
    case ZMK_TRANSPORT_NONE:
        return 0;

    case ZMK_TRANSPORT_USB: {
#if IS_ENABLED(CONFIG_ZMK_USB)
        int err = zmk_usb_hid_send_consumer_report();
        if (err) {
            LOG_ERR("FAILED TO SEND OVER USB: %d", err);
        }
        return err;
#else
        LOG_ERR("USB endpoint is not supported");
        return -ENOTSUP;
#endif /* IS_ENABLED(CONFIG_ZMK_USB) */
    }

    case ZMK_TRANSPORT_BLE: {
#if IS_ENABLED(CONFIG_ZMK_BLE)
        struct zmk_hid_consumer_report *consumer_report = zmk_hid_get_consumer_report();
        int err = zmk_hog_send_consumer_report(&consumer_report->body);
        if (err) {
            LOG_ERR("FAILED TO SEND OVER HOG: %d", err);
        }
        return err;
#else
        LOG_ERR("BLE HOG endpoint is not supported");
        return -ENOTSUP;
#endif /* IS_ENABLED(CONFIG_ZMK_BLE) */
    }
    }

    LOG_ERR("Unhandled endpoint transport %d", current_instance.transport);
    return -ENOTSUP;
}

int zmk_endpoint_send_report(uint16_t usage_page) {
    LOG_DBG("11111usage page 0x%02X", usage_page);
    switch (usage_page) {
    case HID_USAGE_KEY:
        return send_keyboard_report();

    case HID_USAGE_CONSUMER:
        return send_consumer_report();
    }

    LOG_ERR("Unsupported usage page %d", usage_page);
    return -ENOTSUP;
}

#if IS_ENABLED(CONFIG_ZMK_POINTING)
int zmk_endpoint_send_mouse_report() {
    switch (current_instance.transport) {
    case ZMK_TRANSPORT_NONE:
        return 0;

    case ZMK_TRANSPORT_USB: {
#if IS_ENABLED(CONFIG_ZMK_USB)
        int err = zmk_usb_hid_send_mouse_report();
        if (err) {
            LOG_ERR("FAILED TO SEND OVER USB: %d", err);
        }
        return err;
#else
        LOG_ERR("USB endpoint is not supported");
        return -ENOTSUP;
#endif /* IS_ENABLED(CONFIG_ZMK_USB) */
    }

    case ZMK_TRANSPORT_BLE: {
#if IS_ENABLED(CONFIG_ZMK_BLE)
        struct zmk_hid_mouse_report *mouse_report = zmk_hid_get_mouse_report();
        int err = zmk_hog_send_mouse_report(&mouse_report->body);
        if (err) {
            LOG_ERR("FAILED TO SEND OVER HOG: %d", err);
        }
        return err;
#else
        LOG_ERR("BLE HOG endpoint is not supported");
        return -ENOTSUP;
#endif /* IS_ENABLED(CONFIG_ZMK_BLE) */
    }
    }

    LOG_ERR("Unhandled endpoint transport %d", current_instance.transport);
    return -ENOTSUP;
}
#endif // IS_ENABLED(CONFIG_ZMK_POINTING)

#if IS_ENABLED(CONFIG_SETTINGS)

// Type for the deprecated SETTING_PREFERRED_TRANSPORT_V1 setting. To maintain backwards
// compatibility when ZMK_TRANSPORT_NONE was inserted into the beginning of enum zmk_transport, the
// setting was moved to SETTING_PREFERRED_TRANSPORT. If the deprecated setting exists, it must be
// upgraded to the new type and setting name.
enum transport_v1 {
    TRANSPORT_V1_USB = 0,
    TRANSPORT_V1_BLE = 1,
};

static enum zmk_transport upgrade_transport_v1(enum transport_v1 value) {
    switch (value) {
    case TRANSPORT_V1_USB:
        return ZMK_TRANSPORT_USB;

    case TRANSPORT_V1_BLE:
        return ZMK_TRANSPORT_BLE;
    };

    LOG_ERR("Invalid transport_v1 value: %d", value);
    return ZMK_TRANSPORT_USB;
}

/**
 * Loads the deprecated SETTING_PREFERRED_TRANSPORT_V1 setting and upgrades it to the new type,
 * storing the value in SETTING_PREFERRED_TRANSPORT and deleting the original setting.
 */
static int endpoint_settings_load_preferred_v1(size_t len, settings_read_cb read_cb, void *cb_arg) {
    enum transport_v1 value;

    if (len != sizeof(value)) {
        LOG_ERR("Invalid zmk_transport size (got %zu expected %zu)", len, sizeof(value));
        return -EINVAL;
    }

    ssize_t len_read = read_cb(cb_arg, &value, sizeof(value));
    if (len_read < 0) {
        LOG_ERR("Failed to read preferred endpoint v1 from settings (err %d)", len_read);
        return len_read;
    }

    preferred_transport = upgrade_transport_v1(value);

    int err = settings_delete(SETTING_PREFERRED_TRANSPORT_V1);
    if (err != 0) {
        LOG_ERR("Failed to delete preferred endpoint v1 setting (err %d)", err);
        return err;
    }

    err = settings_save_one(SETTING_PREFERRED_TRANSPORT, &preferred_transport, sizeof(preferred_transport));
    if (err == 0) {
        LOG_INF("Upgraded preferred endpoint setting");
    } else {
        LOG_ERR("Failed to save upgraded endpoint value (err %d)", err);
    }

    return err;
}

/**
 * Loads the SETTING_PREFERRED_TRANSPORT setting.
 */
static int endpoint_settings_load_preferred_v2(size_t len, settings_read_cb read_cb, void *cb_arg) {
    if (len != sizeof(preferred_transport)) {
        LOG_ERR("Invalid zmk_transport size (got %zu expected %zu)", len, sizeof(preferred_transport));
        return -EINVAL;
    }

    ssize_t len_read = read_cb(cb_arg, &preferred_transport, sizeof(preferred_transport));
    if (len_read < 0) {
        LOG_ERR("Failed to read preferred endpoint from settings (err %d)", len_read);
        return len_read;
    }

    return 0;
}

static int endpoint_settings_set(const char *name, size_t len, settings_read_cb read_cb, void *cb_arg) {
    LOG_DBG("Setting endpoint value %s", name);

    if (settings_name_steq(name, SETTING_PREFERRED_TRANSPORT_KEY, NULL)) {
        return endpoint_settings_load_preferred_v2(len, read_cb, cb_arg);
    }

    if (settings_name_steq(name, SETTING_PREFERRED_TRANSPORT_V1_KEY, NULL)) {
        return endpoint_settings_load_preferred_v1(len, read_cb, cb_arg);
    }

    return 0;
}

static int endpoint_settings_commit(void) {
    update_current_endpoint();
    return 0;
}

SETTINGS_STATIC_HANDLER_DEFINE(endpoints, SETTING_SUBTREE, NULL, endpoint_settings_set, endpoint_settings_commit, NULL);

#endif /* IS_ENABLED(CONFIG_SETTINGS) */

static bool is_usb_ready(void) {
#if IS_ENABLED(CONFIG_ZMK_USB)
    return zmk_usb_is_hid_ready();
#else
    return false;
#endif
}

static bool is_ble_ready(void) {
#if IS_ENABLED(CONFIG_ZMK_BLE)
    return zmk_ble_active_profile_is_connected();
#else
    return false;
#endif
}

static enum zmk_transport get_selected_transport(void) {
    switch (preferred_transport) {
    case ZMK_TRANSPORT_NONE:
        LOG_DBG("No endpoint transport selected");
        return ZMK_TRANSPORT_NONE;

    case ZMK_TRANSPORT_USB:
        if (is_usb_ready()) {
            LOG_DBG("USB is preferred and ready");
            return ZMK_TRANSPORT_USB;
        }
        if (is_ble_ready()) {
            LOG_DBG("USB is not ready. Falling back to BLE");
            return ZMK_TRANSPORT_BLE;
        }
        break;

    case ZMK_TRANSPORT_BLE:
        if (is_ble_ready()) {
            LOG_DBG("BLE is preferred and ready");
            return ZMK_TRANSPORT_BLE;
        }
        if (is_usb_ready()) {
            LOG_DBG("BLE is not ready. Falling back to USB");
            return ZMK_TRANSPORT_USB;
        }
        break;
    }

    LOG_DBG("Preferred endpoint transport is %d but no transports are ready", preferred_transport);
    return ZMK_TRANSPORT_NONE;
}

static struct zmk_endpoint_instance get_selected_instance(void) { return get_instance_from_transport(get_selected_transport()); }

static int zmk_endpoints_init(void) {
#if IS_ENABLED(CONFIG_SETTINGS)
    k_work_init_delayable(&endpoints_save_work, endpoints_save_preferred_work);
#endif

    current_instance = get_selected_instance();

    return 0;
}

void zmk_endpoint_clear_reports(void) {
    zmk_hid_keyboard_clear();
    zmk_hid_consumer_clear();
#if IS_ENABLED(CONFIG_ZMK_POINTING)
    zmk_hid_mouse_clear();
#endif // IS_ENABLED(CONFIG_ZMK_POINTING)

    zmk_endpoint_send_report(HID_USAGE_KEY);
    zmk_endpoint_send_report(HID_USAGE_CONSUMER);
}

static void update_current_endpoint(void) {
    struct zmk_endpoint_instance new_instance = get_selected_instance();

    if (!zmk_endpoint_instance_eq(new_instance, current_instance)) {
        // Cancel all current keypresses so keys don't stay held on the old endpoint.
        zmk_endpoint_clear_reports();

        current_instance = new_instance;

        char endpoint_str[ZMK_ENDPOINT_STR_LEN];
        zmk_endpoint_instance_to_str(current_instance, endpoint_str, sizeof(endpoint_str));
        LOG_INF("Endpoint changed: %s", endpoint_str);

        raise_zmk_endpoint_changed((struct zmk_endpoint_changed){.endpoint = current_instance});
    }
}

static int endpoint_listener(const zmk_event_t *eh) {
    update_current_endpoint();
    return 0;
}

ZMK_LISTENER(endpoint_listener, endpoint_listener);
#if IS_ENABLED(CONFIG_ZMK_USB)
ZMK_SUBSCRIPTION(endpoint_listener, zmk_usb_conn_state_changed);
#endif
#if IS_ENABLED(CONFIG_ZMK_BLE)
ZMK_SUBSCRIPTION(endpoint_listener, zmk_ble_active_profile_changed);
#endif

SYS_INIT(zmk_endpoints_init, APPLICATION, CONFIG_APPLICATION_INIT_PRIORITY);
```
